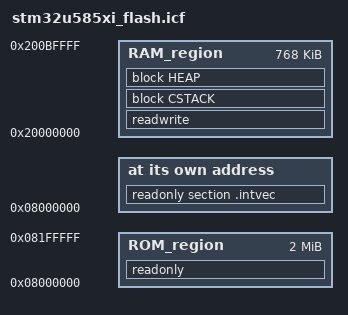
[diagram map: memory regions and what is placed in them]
/*
******************************************************************************
**
**  File        : stm32u585xi_flash.icf
**
**  Abstract    : Linker script for stm32u585xi Device from STM32U585 series
**                      2Mbytes FLASH
**                      768Kbytes RAM
**
**                Set heap size, stack size and stack location according
**                to application requirements.
**
**                Set memory bank area and size if external memory is used.
**
**  Target      : STMicroelectronics STM32
**
**  Distribution: The file is distributed as is without any warranty
**                of any kind.
**
*****************************************************************************
** @attention
**
** Copyright (c) 2023-2024 STMicroelectronics.
** All rights reserved.
**
** This software is licensed under terms that can be found in the LICENSE file
** in the root directory of this software component.
** If no LICENSE file comes with this software, it is provided AS-IS.
**
*****************************************************************************
*/

/*###ICF### Section handled by ICF editor, don't touch! ****/
/*-Editor annotation file-*/
/* IcfEditorFile="$TOOLKIT_DIR$\config\ide\IcfEditor\cortex_v1_0.xml" */
/*-Specials-*/
define symbol __ICFEDIT_intvec_start__ = 0x08000000;
/*-Memory Regions-*/
define symbol __ICFEDIT_region_ROM_start__     = 0x08000000;
define symbol __ICFEDIT_region_ROM_end__       = 0x081FFFFF;
define symbol __ICFEDIT_region_RAM_start__     = 0x20000000;
define symbol __ICFEDIT_region_RAM_end__       = 0x200BFFFF;

/*-Sizes-*/
define symbol __ICFEDIT_size_cstack__ = 0x400;
define symbol __ICFEDIT_size_heap__   = 0x200;
/**** End of ICF editor section. ###ICF###*/


define memory mem with size = 4G;
define region ROM_region      = mem:[from __ICFEDIT_region_ROM_start__   to __ICFEDIT_region_ROM_end__];
define region RAM_region      = mem:[from __ICFEDIT_region_RAM_start__   to __ICFEDIT_region_RAM_end__];

define block CSTACK    with alignment = 8, size = __ICFEDIT_size_cstack__   { };
define block HEAP      with alignment = 8, size = __ICFEDIT_size_heap__     { };

initialize by copy { readwrite };
do not initialize  { section .noinit };

place at address mem:__ICFEDIT_intvec_start__ { readonly section .intvec };

place in ROM_region     { readonly };
place in RAM_region     { readwrite,
                          block CSTACK, block HEAP };
